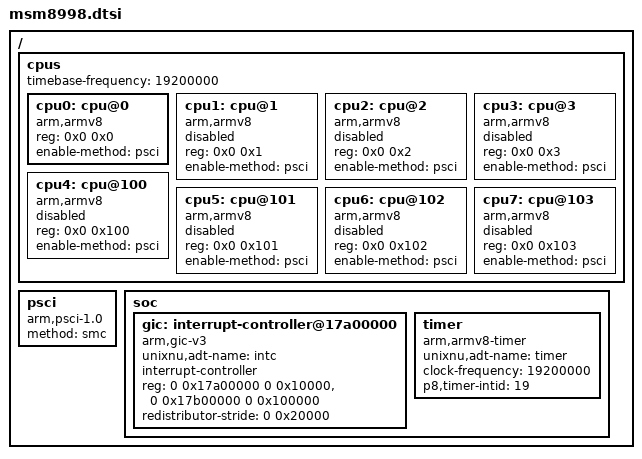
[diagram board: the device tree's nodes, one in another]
// MSM8998 topology, written for this port. Only the first core is enabled
// during bring-up; the others stay disabled until SMP has been qualified.
/ {
	cpus {
		#address-cells = <2>;
		#size-cells = <0>;
		timebase-frequency = <19200000>;

		cpu0: cpu@0 { device_type = "cpu"; compatible = "arm,armv8"; reg = <0x0 0x0>; enable-method = "psci"; status = "okay"; };
		cpu1: cpu@1 { device_type = "cpu"; compatible = "arm,armv8"; reg = <0x0 0x1>; enable-method = "psci"; status = "disabled"; };
		cpu2: cpu@2 { device_type = "cpu"; compatible = "arm,armv8"; reg = <0x0 0x2>; enable-method = "psci"; status = "disabled"; };
		cpu3: cpu@3 { device_type = "cpu"; compatible = "arm,armv8"; reg = <0x0 0x3>; enable-method = "psci"; status = "disabled"; };
		cpu4: cpu@100 { device_type = "cpu"; compatible = "arm,armv8"; reg = <0x0 0x100>; enable-method = "psci"; status = "disabled"; };
		cpu5: cpu@101 { device_type = "cpu"; compatible = "arm,armv8"; reg = <0x0 0x101>; enable-method = "psci"; status = "disabled"; };
		cpu6: cpu@102 { device_type = "cpu"; compatible = "arm,armv8"; reg = <0x0 0x102>; enable-method = "psci"; status = "disabled"; };
		cpu7: cpu@103 { device_type = "cpu"; compatible = "arm,armv8"; reg = <0x0 0x103>; enable-method = "psci"; status = "disabled"; };
	};

	psci { compatible = "arm,psci-1.0"; method = "smc"; };

	soc {
		#address-cells = <2>;
		#size-cells = <2>;
		ranges;

		gic: interrupt-controller@17a00000 {
			compatible = "arm,gic-v3";
			unixnu,adt-name = "intc";
			#address-cells = <2>;
			#size-cells = <2>;
			#interrupt-cells = <3>;
			interrupt-controller;
			reg = <0 0x17a00000 0 0x10000>, <0 0x17b00000 0 0x100000>;
			redistributor-stride = <0 0x20000>;
		};

		timer {
			compatible = "arm,armv8-timer";
			unixnu,adt-name = "timer";
			clock-frequency = <19200000>;
			p8,timer-intid = <19>;
		};
	};
};
